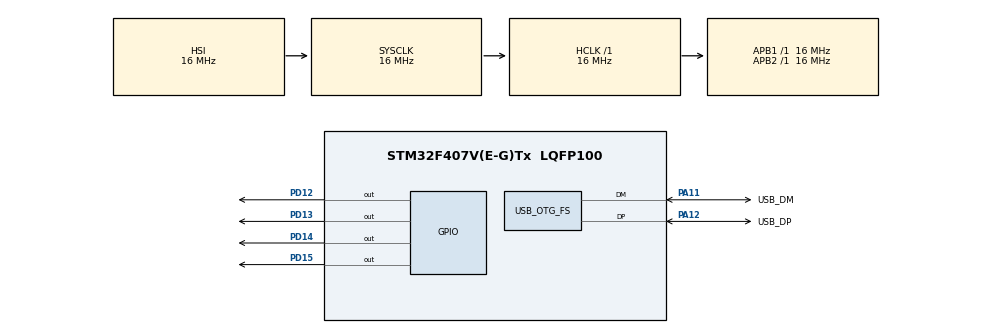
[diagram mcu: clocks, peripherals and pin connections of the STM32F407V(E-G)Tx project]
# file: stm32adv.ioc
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FREERTOS.Tasks01=defaultTask,24,128,StartDefaultTask,Default,NULL
Mcu.Family=STM32F4
Mcu.Name=STM32F407V(E-G)Tx
Mcu.Package=LQFP100
NVIC.OTG_FS_IRQn=true\:5\:0\:false\:false\:true\:true\:true\:true
NVIC.PriorityGroup=NVIC_PRIORITYGROUP_4
NVIC.TIM1_UP_TIM10_IRQn=true\:0\:0\:false\:false\:true\:false\:false\:true
NVIC.TimeBase=TIM1_UP_TIM10_IRQn
NVIC.TimeBaseIP=TIM1
PA11.GPIO_Label=USB_DM
PA11.Mode=Host_Only
PA11.Signal=USB_OTG_FS_DM
PA12.GPIO_Label=USB_DP
PA12.Mode=Host_Only
PA12.Signal=USB_OTG_FS_DP
PD12.Signal=GPIO_Output
PD13.Signal=GPIO_Output
PD14.Signal=GPIO_Output
PD15.Signal=GPIO_Output
PH0-OSC_IN.Mode=HSE-External-Oscillator
PH0-OSC_IN.Signal=RCC_OSC_IN
PH1-OSC_OUT.Mode=HSE-External-Oscillator
PH1-OSC_OUT.Signal=RCC_OSC_OUT
ProjectManager.HeapSize=0x200
ProjectManager.StackSize=0x400
ProjectManager.TargetToolchain=STM32CubeIDE
RCC.48MHZClocksFreq_Value=48000000
RCC.AHBFreq_Value=16000000
RCC.APB1Freq_Value=16000000
RCC.APB2Freq_Value=16000000
RCC.CortexFreq_Value=16000000
RCC.HSE_VALUE=25000000
RCC.HSI_VALUE=16000000
RCC.LSE_VALUE=32768
RCC.PLLM=15
RCC.PLLN=144
RCC.PLLQ=5
RCC.SYSCLKFreq_VALUE=16000000
RCC.VCOOutputFreq_Value=240000000
USB_OTG_FS.VirtualMode=Host_Only
USB_OTG_FS.phy_itface=HCD_PHY_EMBEDDED
VP_FATFS_VS_Generic.Mode=User_defined
VP_FREERTOS_VS_CMSIS_V2.Mode=CMSIS_V2
VP_SYS_VS_tim1.Mode=TIM1
board=custom

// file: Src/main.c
/* USER CODE BEGIN Header */
/**
  ******************************************************************************
  * @file           : main.c
  * @brief          : Main program body
  ******************************************************************************
  * @attention
  *
  * <h2><center>&copy; Copyright (c) 2019 STMicroelectronics.
  * All rights reserved.</center></h2>
  *
  * This software component is licensed by ST under BSD 3-Clause license,
  * the "License"; You may not use this file except in compliance with the
  * License. You may obtain a copy of the License at:
  *                        opensource.org/licenses/BSD-3-Clause
  *
  ******************************************************************************
  */
/* USER CODE END Header */

#include "main.h"
#include "cmsis_os.h"
#include "fatfs.h"

HCD_HandleTypeDef hhcd_USB_OTG_FS;

osThreadId_t defaultTaskHandle;

void SystemClock_Config(void);
static void MX_GPIO_Init(void);
static void MX_USB_OTG_FS_HCD_Init(void);
void StartDefaultTask(void *argument);

int main(void)
{

  /* MCU Configuration--------------------------------------------------------*/

  /* Reset of all peripherals, Initializes the Flash interface and the Systick. */
  HAL_Init();

  /* Configure the system clock */
  SystemClock_Config();

  /* Initialize all configured peripherals */
  MX_GPIO_Init();
  MX_USB_OTG_FS_HCD_Init();

  osKernelInitialize();

  /* Create the thread(s) */
  /* definition and creation of defaultTask */
  const osThreadAttr_t defaultTask_attributes = {
    .name = "defaultTask",
    .priority = (osPriority_t) osPriorityNormal,
    .stack_size = 128
  };
  defaultTaskHandle = osThreadNew(StartDefaultTask, NULL, &defaultTask_attributes);

  /* Start scheduler */
  osKernelStart();

  /* We should never get here as control is now taken by the scheduler */

  /* Infinite loop */
  while (1)
  {

  }
}

void SystemClock_Config(void)
{
  RCC_OscInitTypeDef RCC_OscInitStruct = {0};
  RCC_ClkInitTypeDef RCC_ClkInitStruct = {0};

  /** Configure the main internal regulator output voltage
  */
  __HAL_RCC_PWR_CLK_ENABLE();
  __HAL_PWR_VOLTAGESCALING_CONFIG(PWR_REGULATOR_VOLTAGE_SCALE1);
  /** Initializes the CPU, AHB and APB busses clocks
  */
  RCC_OscInitStruct.OscillatorType = RCC_OSCILLATORTYPE_HSI|RCC_OSCILLATORTYPE_HSE;
  RCC_OscInitStruct.HSEState = RCC_HSE_ON;
  RCC_OscInitStruct.HSIState = RCC_HSI_ON;
  RCC_OscInitStruct.HSICalibrationValue = RCC_HSICALIBRATION_DEFAULT;
  RCC_OscInitStruct.PLL.PLLState = RCC_PLL_ON;
  RCC_OscInitStruct.PLL.PLLSource = RCC_PLLSOURCE_HSE;
  RCC_OscInitStruct.PLL.PLLM = 15;
  RCC_OscInitStruct.PLL.PLLN = 144;
  RCC_OscInitStruct.PLL.PLLP = RCC_PLLP_DIV2;
  RCC_OscInitStruct.PLL.PLLQ = 5;
  if (HAL_RCC_OscConfig(&RCC_OscInitStruct) != HAL_OK)
  {
    Error_Handler();
  }
  /** Initializes the CPU, AHB and APB busses clocks
  */
  RCC_ClkInitStruct.ClockType = RCC_CLOCKTYPE_HCLK|RCC_CLOCKTYPE_SYSCLK
                              |RCC_CLOCKTYPE_PCLK1|RCC_CLOCKTYPE_PCLK2;
  RCC_ClkInitStruct.SYSCLKSource = RCC_SYSCLKSOURCE_HSI;
  RCC_ClkInitStruct.AHBCLKDivider = RCC_SYSCLK_DIV1;
  RCC_ClkInitStruct.APB1CLKDivider = RCC_HCLK_DIV1;
  RCC_ClkInitStruct.APB2CLKDivider = RCC_HCLK_DIV1;

  if (HAL_RCC_ClockConfig(&RCC_ClkInitStruct, FLASH_LATENCY_0) != HAL_OK)
  {
    Error_Handler();
  }
}

static void MX_USB_OTG_FS_HCD_Init(void)
{

  hhcd_USB_OTG_FS.Instance = USB_OTG_FS;
  hhcd_USB_OTG_FS.Init.Host_channels = 8;
  hhcd_USB_OTG_FS.Init.speed = HCD_SPEED_FULL;
  hhcd_USB_OTG_FS.Init.dma_enable = DISABLE;
  hhcd_USB_OTG_FS.Init.phy_itface = HCD_PHY_EMBEDDED;
  hhcd_USB_OTG_FS.Init.Sof_enable = DISABLE;
  if (HAL_HCD_Init(&hhcd_USB_OTG_FS) != HAL_OK)
  {
    Error_Handler();
  }

}

static void MX_GPIO_Init(void)
{
  GPIO_InitTypeDef GPIO_InitStruct = {0};

  /* GPIO Ports Clock Enable */
  __HAL_RCC_GPIOH_CLK_ENABLE();
  __HAL_RCC_GPIOD_CLK_ENABLE();
  __HAL_RCC_GPIOA_CLK_ENABLE();

  /*Configure GPIO pin Output Level */
  HAL_GPIO_WritePin(GPIOD, GPIO_PIN_12|GPIO_PIN_13|GPIO_PIN_14|GPIO_PIN_15, GPIO_PIN_RESET);

  /*Configure GPIO pins : PD12 PD13 PD14 PD15 */
  GPIO_InitStruct.Pin = GPIO_PIN_12|GPIO_PIN_13|GPIO_PIN_14|GPIO_PIN_15;
  GPIO_InitStruct.Mode = GPIO_MODE_OUTPUT_PP;
  GPIO_InitStruct.Pull = GPIO_NOPULL;
  GPIO_InitStruct.Speed = GPIO_SPEED_FREQ_LOW;
  HAL_GPIO_Init(GPIOD, &GPIO_InitStruct);

}

void StartDefaultTask(void *argument)
{

  /* init code for FATFS */
  MX_FATFS_Init();

  /* USER CODE BEGIN 5 */
  /* Infinite loop */
  for(;;)
  {
    /* This behavior mean that in main application,
     * Yellow led will be blinking every 0.5s
     * Just it.
     */
    HAL_GPIO_TogglePin(GPIOD, GPIO_PIN_12);
    osDelay(500);
  }
  /* USER CODE END 5 */
}

void HAL_TIM_PeriodElapsedCallback(TIM_HandleTypeDef *htim)
{
  if (htim->Instance == TIM1) {
    HAL_IncTick();
  }
}

void Error_Handler(void)
{
}

/************************ (C) COPYRIGHT STMicroelectronics *****END OF FILE****/
